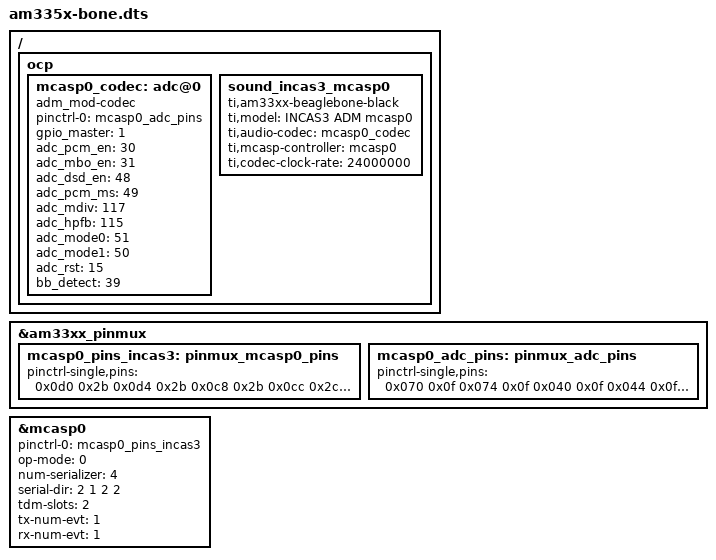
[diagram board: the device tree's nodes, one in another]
/*
 * Copyright (C) 2012 Texas Instruments Incorporated - http://www.ti.com/
 *
 * This program is free software; you can redistribute it and/or modify
 * it under the terms of the GNU General Public License version 2 as
 * published by the Free Software Foundation.
 */
/dts-v1/;

/include/ "am33xx.dtsi"

/include/ "am335x-bone-common.dtsi"

&am33xx_pinmux {
    mcasp0_pins_incas3: pinmux_mcasp0_pins {
		pinctrl-single,pins = <
            /* mcasp0 input */
            0x0d0 0x2b /* aclkr p8_35, MUX_MODE3 | PIN_INPUT_PULLDOWN */
            0x0d4 0x2b /* fsr   p8_33, MUX_MODE3 | PIN_INPUT_PULLDOWN */
            0x0c8 0x2b /* axr0  p8_36, MUX_MODE3 | PIN_INPUT_PULLDOWN */
            0x0cc 0x2c /* axr2  p8_34, MUX_MODE4 | PIN_INPUT_PULLDOWN */
            0x0dc 0x2c /* axr3  p8_32, MUX_MODE4 | PIN_INPUT_PULLDOWN */
            0x0ec 0x27 /* gpio2_25  p8_30, MUX_MODE7 | PIN_INPUT */

            /* mcasp0 output */
            0x0c0 0x2b /* aclkx p8_37, MUX_MODE3 | PIN_INPUT_PULLDOWN */
            0x0c4 0x2b /* fsx   p8_38, MUX_MODE3 | PIN_INPUT_PULLDOWN */
            0x0d8 0x0b /* axr1  p8_31, MUX_MODE3 | PIN_OUTPUT */
        >;
    };

    mcasp0_adc_pins: pinmux_adc_pins {
		pinctrl-single,pins = <
            0x070 0x0f /* p9_11, MUX_MODE7 | PIN_OUTPUT adc_pcm_en */
            0x074 0x0f /* p9_13, MUX_MODE7 | PIN_OUTPUT adc_mbo_en */
            0x040 0x0f /* p9_15, MUX_MODE7 | PIN_OUTPUT adc_dsd_en */
            0x044 0x0f /* p9_23, MUX_MODE7 | PIN_OUTPUT adc_pcm_ms */
            0x1ac 0x0f /* p9_25, MUX_MODE7 | PIN_OUTPUT adc_mdiv */
            0x180 0x0f /* p9_27, MUX_MODE7 | PIN_OUTPUT adc_hpfb */
            0x048 0x0f /* p9_14, MUX_MODE7 | PIN_OUTPUT adc_mode0 */
            0x04c 0x0f /* p9_16, MUX_MODE7 | PIN_OUTPUT adc_mode1 */
            0x184 0x0f /* p9_24, MUX_MODE7 | PIN_OUTPUT adc_rst */
            0x01c 0x0f /* p8_04, MUX_MODE7 | PIN_OUTPUT bb_detect */
        >;
    };
};

&mcasp0 {
    pinctrl-names = "default";
    pinctrl-0 = <&mcasp0_pins_incas3>;

    status = "okay";

    op-mode = <0>; /*  MCASP_IIS_MODE */
    num-serializer = <4>;
    serial-dir = < 2 1 2 2>; /* 0: INACTIVE, 1: TX, 2: RX */
    tdm-slots = <2>;

    tx-num-evt = <1>;
    rx-num-evt = <1>;
};

/ {
    ocp {
        mcasp0_codec: adc@0 { 
            compatible = "adm_mod-codec";
            status = "okay";
            pinctrl-names = "default";
            pinctrl-0 = <&mcasp0_adc_pins>;

            gpio_master = <1>;

            /* 32 * <bank> + <gpio> */
            adc_pcm_en = <30>; /* pin a11: gpio0[30] */
            adc_mbo_en = <31>; /* pin a13: gpio0[31] */ 
            adc_dsd_en = <48>; /* pin a15: gpio1[16] */ 
            adc_pcm_ms = <49>; /* pin a23: gpio1[17] */
            adc_mdiv = <117>; /* pin a25: gpio3[21] */
            adc_hpfb = <115>; /* pin a27: gpio3[19] */
            adc_mode0 = <51>; /* pin a14: gpio1[19] */
            adc_mode1 = <50>; /* pin a16: gpio1[18] */
            adc_rst = <15>; /* pin a24: gpio0[15] */
            bb_detect = <39>; /* pin b04: gpio1[7] */ /* Different from the bbb! */
        };

        sound_incas3_mcasp0 {
            compatible = "ti,am33xx-beaglebone-black";
            ti,model = "INCAS3 ADM mcasp0";
            ti,audio-codec = <&mcasp0_codec>;
            ti,mcasp-controller = <&mcasp0>;
            ti,codec-clock-rate = <24000000>;
        };
    };
};
